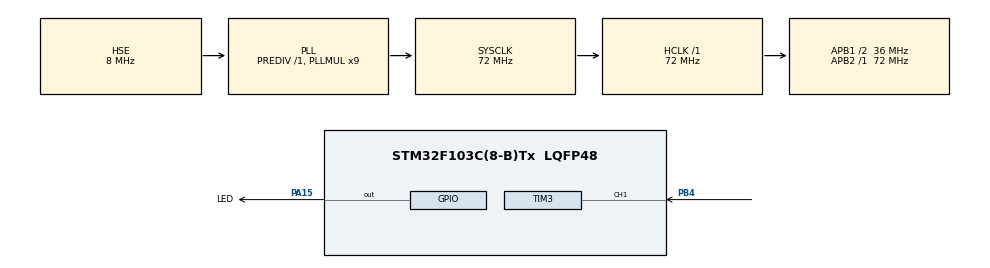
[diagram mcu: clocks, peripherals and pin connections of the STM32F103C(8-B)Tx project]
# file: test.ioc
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Dma.Request0=TIM3_CH1/TRIG
Dma.TIM3_CH1/TRIG.0.Direction=DMA_PERIPH_TO_MEMORY
Dma.TIM3_CH1/TRIG.0.Instance=DMA1_Channel6
Dma.TIM3_CH1/TRIG.0.MemDataAlignment=DMA_MDATAALIGN_HALFWORD
Dma.TIM3_CH1/TRIG.0.MemInc=DMA_MINC_ENABLE
Dma.TIM3_CH1/TRIG.0.Mode=DMA_NORMAL
Dma.TIM3_CH1/TRIG.0.PeriphDataAlignment=DMA_PDATAALIGN_HALFWORD
Dma.TIM3_CH1/TRIG.0.PeriphInc=DMA_PINC_DISABLE
Dma.TIM3_CH1/TRIG.0.Priority=DMA_PRIORITY_MEDIUM
Mcu.Family=STM32F1
Mcu.Name=STM32F103C(8-B)Tx
Mcu.Package=LQFP48
NVIC.DMA1_Channel6_IRQn=true\:0\:0\:false\:false\:true\:false
NVIC.PriorityGroup=NVIC_PRIORITYGROUP_4
NVIC.TIM2_IRQn=true\:0\:0\:false\:false\:true\:true
NVIC.TIM3_IRQn=true\:0\:0\:false\:false\:true\:true
NVIC.TIM4_IRQn=true\:0\:0\:false\:false\:true\:true
PA13.Mode=Serial_Wire
PA13.Signal=SYS_JTMS-SWDIO
PA14.Mode=Serial_Wire
PA14.Signal=SYS_JTCK-SWCLK
PA15.GPIO_Label=LED
PA15.GPIO_ModeDefaultOutputPP=GPIO_MODE_OUTPUT_PP
PA15.GPIO_Speed=GPIO_SPEED_FREQ_LOW
PA15.PinState=GPIO_PIN_RESET
PA15.Signal=GPIO_Output
PB4.GPIO_PuPd=GPIO_PULLDOWN
PB4.Signal=S_TIM3_CH1
PD0-OSC_IN.Mode=HSE-External-Oscillator
PD0-OSC_IN.Signal=RCC_OSC_IN
PD1-OSC_OUT.Mode=HSE-External-Oscillator
PD1-OSC_OUT.Signal=RCC_OSC_OUT
ProjectManager.HeapSize=0x200
ProjectManager.StackSize=0x400
ProjectManager.TargetToolchain=MDK-ARM V5
RCC.AHBFreq_Value=72000000
RCC.APB1CLKDivider=RCC_HCLK_DIV2
RCC.APB1Freq_Value=36000000
RCC.APB1TimFreq_Value=72000000
RCC.APB2Freq_Value=72000000
RCC.APB2TimFreq_Value=72000000
RCC.HCLKFreq_Value=72000000
RCC.PLLMUL=RCC_PLL_MUL9
RCC.PLLSourceVirtual=RCC_PLLSOURCE_HSE
RCC.SYSCLKFreq_VALUE=72000000
RCC.SYSCLKSource=RCC_SYSCLKSOURCE_PLLCLK
RCC.USBFreq_Value=72000000
SH.S_TIM3_CH1.0=TIM3_CH1,Input_Capture1_from_TI1
TIM2.Period=60
TIM2.Prescaler=71
TIM3.Channel-Input_Capture1_from_TI1=TIM_CHANNEL_1
TIM3.Period=0xffff
TIM3.Prescaler=71
VP_TIM2_VS_ClockSourceINT.Mode=Internal
VP_TIM3_VS_ClockSourceINT.Mode=Internal
VP_TIM4_VS_ClockSourceINT.Mode=Internal
board=test

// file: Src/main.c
/**
  ******************************************************************************
  * @file           : main.c
  * @brief          : Main program body
  ******************************************************************************
  ** This notice applies to any and all portions of this file
  * that are not between comment pairs USER CODE BEGIN and
  * USER CODE END. Other portions of this file, whether
  * inserted by the user or by software development tools
  * are owned by their respective copyright owners.
  *
  * COPYRIGHT(c) 2018 STMicroelectronics
  *
  * Redistribution and use in source and binary forms, with or without modification,
  * are permitted provided that the following conditions are met:
  *   1. Redistributions of source code must retain the above copyright notice,
  *      this list of conditions and the following disclaimer.
  *   2. Redistributions in binary form must reproduce the above copyright notice,
  *      this list of conditions and the following disclaimer in the documentation
  *      and/or other materials provided with the distribution.
  *   3. Neither the name of STMicroelectronics nor the names of its contributors
  *      may be used to endorse or promote products derived from this software
  *      without specific prior written permission.
  *
  * THIS SOFTWARE IS PROVIDED BY THE COPYRIGHT HOLDERS AND CONTRIBUTORS "AS IS"
  * AND ANY EXPRESS OR IMPLIED WARRANTIES, INCLUDING, BUT NOT LIMITED TO, THE
  * IMPLIED WARRANTIES OF MERCHANTABILITY AND FITNESS FOR A PARTICULAR PURPOSE ARE
  * DISCLAIMED. IN NO EVENT SHALL THE COPYRIGHT HOLDER OR CONTRIBUTORS BE LIABLE
  * FOR ANY DIRECT, INDIRECT, INCIDENTAL, SPECIAL, EXEMPLARY, OR CONSEQUENTIAL
  * DAMAGES (INCLUDING, BUT NOT LIMITED TO, PROCUREMENT OF SUBSTITUTE GOODS OR
  * SERVICES; LOSS OF USE, DATA, OR PROFITS; OR BUSINESS INTERRUPTION) HOWEVER
  * CAUSED AND ON ANY THEORY OF LIABILITY, WHETHER IN CONTRACT, STRICT LIABILITY,
  * OR TORT (INCLUDING NEGLIGENCE OR OTHERWISE) ARISING IN ANY WAY OUT OF THE USE
  * OF THIS SOFTWARE, EVEN IF ADVISED OF THE POSSIBILITY OF SUCH DAMAGE.
  *
  ******************************************************************************
  */
#include "main.h"
#include "stm32f1xx_hal.h"

/* USER CODE BEGIN Includes */
#include "delay.h"
/* USER CODE END Includes */

TIM_HandleTypeDef htim2;
TIM_HandleTypeDef htim3;
TIM_HandleTypeDef htim4;
DMA_HandleTypeDef hdma_tim3_ch1_trig;

/* USER CODE BEGIN PV */
/* Private variables ---------------------------------------------------------*/

/* USER CODE END PV */

void SystemClock_Config(void);
static void MX_GPIO_Init(void);
static void MX_DMA_Init(void);
static void MX_TIM3_Init(void);
static void MX_TIM4_Init(void);
static void MX_TIM2_Init(void);

/* USER CODE BEGIN PFP */
/* Private function prototypes -----------------------------------------------*/
void TIM3_CH1_Cap_Init(uint32_t arr,uint16_t psc);
/* USER CODE END PFP */

/* USER CODE BEGIN 0 */
uint8_t TIM3CH1_CAPTURE_STA=0;//输入捕获状态
uint32_t TIM3CH1_CAPTURE_VAL=0; //输入捕获值
	uint8_t Probe_L=0;// 做探头数据
	uint8_t Probe_LM=0;
	uint8_t Probe_R=0;
	uint8_t Probe_RM=0;
	uint8_t Data_Bit[19]={0};
/* USER CODE END 0 */

int main(void)
{

  /* MCU Configuration----------------------------------------------------------*/

  /* Reset of all peripherals, Initializes the Flash interface and the Systick. */
  HAL_Init();

  /* USER CODE BEGIN Init */
	uint32_t temp=0;	//低电平脉宽
	uint8_t bit=0;
	uint8_t i=0;

	uint8_t beep=0x11;
	uint8_t ChexkBit=0;
	uint32_t Data_Time_Buf[19]={0};

  /* USER CODE END Init */

  /* Configure the system clock */
  SystemClock_Config();

  /* Initialize all configured peripherals */
  MX_GPIO_Init();
  MX_DMA_Init();
  MX_TIM3_Init();
  MX_TIM4_Init();
  MX_TIM2_Init();
  /* USER CODE BEGIN 2 */
	delay_init(72);
	HAL_TIM_IC_Start_IT(&htim3,TIM_CHANNEL_1);//开启TIM3的捕获通道1，并且开启捕获中断
	__HAL_TIM_ENABLE_IT(&htim3,TIM_IT_UPDATE); //使能更新中断
//	TIM3_CH1_Cap_Init(0XFFFF,72-1);		//以1Mhz的频率计数
  /* USER CODE END 2 */

  /* Infinite loop */
  /* USER CODE BEGIN WHILE */
  while (1)
  {
//		HAL_TIM_IC_Start_DMA(&htim3,TIM_CHANNEL_1,Data_Time_Buf,19);
		//Delay_ms(500);
		if(TIM3CH1_CAPTURE_STA&0x80)//成功捕捉到上升沿
		{
			temp=TIM3CH1_CAPTURE_STA&0X3F;
			temp*=50; //溢出时间总和
			temp+=TIM3CH1_CAPTURE_VAL; //得到总的低电平时间
			if(temp>1449&&temp<1551)
			{
				HAL_GPIO_TogglePin(LED_GPIO_Port, LED_Pin);
				TIM3CH1_CAPTURE_STA=0; //开启下一次捕获
				for(i=0;i<19;)
				{
					if(TIM3CH1_CAPTURE_STA&0x80)
					{
						temp=TIM3CH1_CAPTURE_STA&0X3F;
						temp*=50; //溢出时间总和
						temp+=TIM3CH1_CAPTURE_VAL; //得到总的低电平时间
						Data_Time_Buf[i]=temp;
						i++;
						TIM3CH1_CAPTURE_STA=0; //开启下一次捕获
					}
				}
				ChexkBit=0;
				for(i=0;i<19;i++)
				{
					if(*(Data_Time_Buf+i)>125)
						Data_Bit[i]=0;
					else
						Data_Bit[i]=1;
					ChexkBit+=Data_Bit[i];
				}
				if(ChexkBit%2==Data_Bit[18])
				{
					Probe_L=(Data_Bit[0]|Data_Bit[1]<<1|Data_Bit[2]<<2|Data_Bit[3]<<3)*20+20;
					Probe_LM=(Data_Bit[4]|Data_Bit[5]<<1|Data_Bit[6]<<2|Data_Bit[7]<<3)*20+20;
					Probe_RM=(Data_Bit[8]|Data_Bit[9]<<1|Data_Bit[10]<<2|Data_Bit[11]<<3)*20+20;
					Probe_R=(Data_Bit[12]|Data_Bit[13]<<1|Data_Bit[14]<<2|Data_Bit[15]<<3)*20+20;
				}
			}
 			TIM3CH1_CAPTURE_STA=0; //开启下一次捕获
		}
  /* USER CODE END WHILE */

  }

}

void SystemClock_Config(void)
{

  RCC_OscInitTypeDef RCC_OscInitStruct;
  RCC_ClkInitTypeDef RCC_ClkInitStruct;

    /**Initializes the CPU, AHB and APB busses clocks
    */
  RCC_OscInitStruct.OscillatorType = RCC_OSCILLATORTYPE_HSE;
  RCC_OscInitStruct.HSEState = RCC_HSE_ON;
  RCC_OscInitStruct.HSEPredivValue = RCC_HSE_PREDIV_DIV1;
  RCC_OscInitStruct.HSIState = RCC_HSI_ON;
  RCC_OscInitStruct.PLL.PLLState = RCC_PLL_ON;
  RCC_OscInitStruct.PLL.PLLSource = RCC_PLLSOURCE_HSE;
  RCC_OscInitStruct.PLL.PLLMUL = RCC_PLL_MUL9;
  if (HAL_RCC_OscConfig(&RCC_OscInitStruct) != HAL_OK)
  {
    _Error_Handler(__FILE__, __LINE__);
  }

    /**Initializes the CPU, AHB and APB busses clocks
    */
  RCC_ClkInitStruct.ClockType = RCC_CLOCKTYPE_HCLK|RCC_CLOCKTYPE_SYSCLK
                              |RCC_CLOCKTYPE_PCLK1|RCC_CLOCKTYPE_PCLK2;
  RCC_ClkInitStruct.SYSCLKSource = RCC_SYSCLKSOURCE_PLLCLK;
  RCC_ClkInitStruct.AHBCLKDivider = RCC_SYSCLK_DIV1;
  RCC_ClkInitStruct.APB1CLKDivider = RCC_HCLK_DIV2;
  RCC_ClkInitStruct.APB2CLKDivider = RCC_HCLK_DIV1;

  if (HAL_RCC_ClockConfig(&RCC_ClkInitStruct, FLASH_LATENCY_2) != HAL_OK)
  {
    _Error_Handler(__FILE__, __LINE__);
  }

    /**Configure the Systick interrupt time
    */
  HAL_SYSTICK_Config(HAL_RCC_GetHCLKFreq()/1000);

    /**Configure the Systick
    */
  HAL_SYSTICK_CLKSourceConfig(SYSTICK_CLKSOURCE_HCLK);

  /* SysTick_IRQn interrupt configuration */
  HAL_NVIC_SetPriority(SysTick_IRQn, 0, 0);
}

/* TIM2 init function */
static void MX_TIM2_Init(void)
{

  TIM_ClockConfigTypeDef sClockSourceConfig;
  TIM_MasterConfigTypeDef sMasterConfig;

  htim2.Instance = TIM2;
  htim2.Init.Prescaler = 71;
  htim2.Init.CounterMode = TIM_COUNTERMODE_UP;
  htim2.Init.Period = 60;
  htim2.Init.ClockDivision = TIM_CLOCKDIVISION_DIV1;
  htim2.Init.AutoReloadPreload = TIM_AUTORELOAD_PRELOAD_DISABLE;
  if (HAL_TIM_Base_Init(&htim2) != HAL_OK)
  {
    _Error_Handler(__FILE__, __LINE__);
  }

  sClockSourceConfig.ClockSource = TIM_CLOCKSOURCE_INTERNAL;
  if (HAL_TIM_ConfigClockSource(&htim2, &sClockSourceConfig) != HAL_OK)
  {
    _Error_Handler(__FILE__, __LINE__);
  }

  sMasterConfig.MasterOutputTrigger = TIM_TRGO_RESET;
  sMasterConfig.MasterSlaveMode = TIM_MASTERSLAVEMODE_DISABLE;
  if (HAL_TIMEx_MasterConfigSynchronization(&htim2, &sMasterConfig) != HAL_OK)
  {
    _Error_Handler(__FILE__, __LINE__);
  }

}

/* TIM3 init function */
static void MX_TIM3_Init(void)
{

  TIM_ClockConfigTypeDef sClockSourceConfig;
  TIM_MasterConfigTypeDef sMasterConfig;
  TIM_IC_InitTypeDef sConfigIC;

  htim3.Instance = TIM3;
  htim3.Init.Prescaler = 71;
  htim3.Init.CounterMode = TIM_COUNTERMODE_UP;
  htim3.Init.Period = 50;
  htim3.Init.ClockDivision = TIM_CLOCKDIVISION_DIV1;
  htim3.Init.AutoReloadPreload = TIM_AUTORELOAD_PRELOAD_DISABLE;
  if (HAL_TIM_Base_Init(&htim3) != HAL_OK)
  {
    _Error_Handler(__FILE__, __LINE__);
  }

  sClockSourceConfig.ClockSource = TIM_CLOCKSOURCE_INTERNAL;
  if (HAL_TIM_ConfigClockSource(&htim3, &sClockSourceConfig) != HAL_OK)
  {
    _Error_Handler(__FILE__, __LINE__);
  }

  if (HAL_TIM_IC_Init(&htim3) != HAL_OK)
  {
    _Error_Handler(__FILE__, __LINE__);
  }

  sMasterConfig.MasterOutputTrigger = TIM_TRGO_RESET;
  sMasterConfig.MasterSlaveMode = TIM_MASTERSLAVEMODE_DISABLE;
  if (HAL_TIMEx_MasterConfigSynchronization(&htim3, &sMasterConfig) != HAL_OK)
  {
    _Error_Handler(__FILE__, __LINE__);
  }

  sConfigIC.ICPolarity = TIM_INPUTCHANNELPOLARITY_RISING;
  sConfigIC.ICSelection = TIM_ICSELECTION_DIRECTTI;
  sConfigIC.ICPrescaler = TIM_ICPSC_DIV1;
  sConfigIC.ICFilter = 0;
  if (HAL_TIM_IC_ConfigChannel(&htim3, &sConfigIC, TIM_CHANNEL_1) != HAL_OK)
  {
    _Error_Handler(__FILE__, __LINE__);
  }

}

/* TIM4 init function */
static void MX_TIM4_Init(void)
{

  TIM_ClockConfigTypeDef sClockSourceConfig;
  TIM_MasterConfigTypeDef sMasterConfig;

  htim4.Instance = TIM4;
  htim4.Init.Prescaler = 0;
  htim4.Init.CounterMode = TIM_COUNTERMODE_UP;
  htim4.Init.Period = 0;
  htim4.Init.ClockDivision = TIM_CLOCKDIVISION_DIV1;
  htim4.Init.AutoReloadPreload = TIM_AUTORELOAD_PRELOAD_DISABLE;
  if (HAL_TIM_Base_Init(&htim4) != HAL_OK)
  {
    _Error_Handler(__FILE__, __LINE__);
  }

  sClockSourceConfig.ClockSource = TIM_CLOCKSOURCE_INTERNAL;
  if (HAL_TIM_ConfigClockSource(&htim4, &sClockSourceConfig) != HAL_OK)
  {
    _Error_Handler(__FILE__, __LINE__);
  }

  sMasterConfig.MasterOutputTrigger = TIM_TRGO_RESET;
  sMasterConfig.MasterSlaveMode = TIM_MASTERSLAVEMODE_DISABLE;
  if (HAL_TIMEx_MasterConfigSynchronization(&htim4, &sMasterConfig) != HAL_OK)
  {
    _Error_Handler(__FILE__, __LINE__);
  }

}

static void MX_DMA_Init(void)
{
  /* DMA controller clock enable */
  __HAL_RCC_DMA1_CLK_ENABLE();

  /* DMA interrupt init */
  /* DMA1_Channel6_IRQn interrupt configuration */
  HAL_NVIC_SetPriority(DMA1_Channel6_IRQn, 0, 0);
  HAL_NVIC_EnableIRQ(DMA1_Channel6_IRQn);

}

/** Configure pins as
        * Analog
        * Input
        * Output
        * EVENT_OUT
        * EXTI
*/
static void MX_GPIO_Init(void)
{

  GPIO_InitTypeDef GPIO_InitStruct;

  /* GPIO Ports Clock Enable */
  __HAL_RCC_GPIOD_CLK_ENABLE();
  __HAL_RCC_GPIOA_CLK_ENABLE();
  __HAL_RCC_GPIOB_CLK_ENABLE();

  /*Configure GPIO pin Output Level */
  HAL_GPIO_WritePin(LED_GPIO_Port, LED_Pin, GPIO_PIN_RESET);

  /*Configure GPIO pin : LED_Pin */
  GPIO_InitStruct.Pin = LED_Pin;
  GPIO_InitStruct.Mode = GPIO_MODE_OUTPUT_PP;
  GPIO_InitStruct.Speed = GPIO_SPEED_FREQ_LOW;
  HAL_GPIO_Init(LED_GPIO_Port, &GPIO_InitStruct);

}

/* USER CODE BEGIN 4 */
void TIM3_CH1_Cap_Init(uint32_t arr,uint16_t psc)
{
    TIM_IC_InitTypeDef TIM2_CH2Config;

    htim3.Instance=TIM2;                          //通用定时器2
    htim3.Init.Prescaler=psc;                     //分频系数
    htim3.Init.CounterMode=TIM_COUNTERMODE_UP;    //向上计数器
    htim3.Init.Period=arr;                        //自动装载值
    htim3.Init.ClockDivision=TIM_CLOCKDIVISION_DIV1;//时钟分频银子
    HAL_TIM_IC_Init(&htim3);						//初始化输入捕获时基参数

    TIM2_CH2Config.ICPolarity=TIM_ICPOLARITY_RISING;    //上升沿捕获
    TIM2_CH2Config.ICSelection=TIM_ICSELECTION_DIRECTTI;//映射到TI1上
    TIM2_CH2Config.ICPrescaler=TIM_ICPSC_DIV1;          //配置输入分频，不分频
    TIM2_CH2Config.ICFilter=0;                          //配置输入滤波器，不滤波
    HAL_TIM_IC_ConfigChannel(&htim3,&TIM2_CH2Config,TIM_CHANNEL_1);//配置TIM2通道2

    HAL_TIM_IC_Start_IT(&htim3,TIM_CHANNEL_1);   //开启TIM2的捕获通道2，并且开启捕获中断
    __HAL_TIM_ENABLE_IT(&htim3,TIM_IT_UPDATE);   //使能更新中断

	HAL_NVIC_SetPriority(TIM2_IRQn,2,0);    //设置中断优先级，抢占优先级2，子优先级0
    HAL_NVIC_EnableIRQ(TIM2_IRQn);          //开启ITM2中断通道
}

void HAL_TIM_IC_MspInit(TIM_HandleTypeDef *htim)
{
    GPIO_InitTypeDef GPIO_Initure;
    __HAL_RCC_TIM2_CLK_ENABLE();            //使能TIM2时钟
    __HAL_RCC_GPIOB_CLK_ENABLE();			//开启GPIOB时钟

    GPIO_Initure.Pin=GPIO_PIN_4;            //PB4
    GPIO_Initure.Mode=GPIO_MODE_AF_INPUT; 	//复用推挽输入
    GPIO_Initure.Pull=GPIO_PULLDOWN;        //下拉
    GPIO_Initure.Speed=GPIO_SPEED_FREQ_HIGH;     //高速
    HAL_GPIO_Init(GPIOB,&GPIO_Initure);

    HAL_NVIC_SetPriority(TIM3_IRQn,2,0);    //设置中断优先级，抢占优先级2，子优先级0
    HAL_NVIC_EnableIRQ(TIM3_IRQn);          //开启ITM2中断通道
}

//定时器5中断服务函数
//void TIM3_IRQHandler(void)
//{
//	HAL_TIM_IRQHandler(&htim3);				//定时器共用处理函数
//}

//定时器更新中断（计数溢出）中断处理回调函数， 该函数在HAL_TIM_IRQHandler中会被调用
void HAL_TIM_PeriodElapsedCallback(TIM_HandleTypeDef *htim)//更新中断（溢出）发生时执行
{
	if((TIM3CH1_CAPTURE_STA&0X80)==0)				//还未成功捕获
	{
		if(TIM3CH1_CAPTURE_STA&0X40)				//已经捕获到低电平了
		{
				TIM3CH1_CAPTURE_STA++;
		}
	}
}

//定时器输入捕获中断处理回调函数，该函数在HAL_TIM_IRQHandler中会被调用
void HAL_TIM_IC_CaptureCallback(TIM_HandleTypeDef *htim)//捕获中断发生时执行
{
	if((TIM3CH1_CAPTURE_STA&0X80)==0)				//还未成功捕获
	{
		if(TIM3CH1_CAPTURE_STA&0X40)				//捕获到一个上升沿
		{
			TIM3CH1_CAPTURE_STA|=0X80;				//标记成功捕获到一次高电平脉宽
      TIM3CH1_CAPTURE_VAL=HAL_TIM_ReadCapturedValue(&htim3,TIM_CHANNEL_1);//获取当前的捕获值.
			TIM_RESET_CAPTUREPOLARITY(&htim3,TIM_CHANNEL_1);   //一定要先清除原来的设置！！
      TIM_SET_CAPTUREPOLARITY(&htim3,TIM_CHANNEL_1,TIM_ICPOLARITY_RISING);//配置TIM5通道1下降沿捕获
		}
		else  										//还未开始,第一次捕获下降沿
		{
			TIM3CH1_CAPTURE_STA=0;					//清空
			TIM3CH1_CAPTURE_VAL=0;
			TIM3CH1_CAPTURE_STA|=0X40;				//标记捕获到了下降沿
			__HAL_TIM_DISABLE(&htim3);      	//关闭定时器2
			__HAL_TIM_SET_COUNTER(&htim3,0);
			TIM_RESET_CAPTUREPOLARITY(&htim3,TIM_CHANNEL_1);   //一定要先清除原来的设置！！
			TIM_SET_CAPTUREPOLARITY(&htim3,TIM_CHANNEL_1,TIM_ICPOLARITY_FALLING);//定时器5通道1设置为上升沿捕获
			__HAL_TIM_ENABLE(&htim3);		//使能定时器2
		}
	}
}

/* USER CODE END 4 */

void _Error_Handler(char *file, int line)
{
  while(1)
  {
  }
}

/************************ (C) COPYRIGHT STMicroelectronics *****END OF FILE****/
